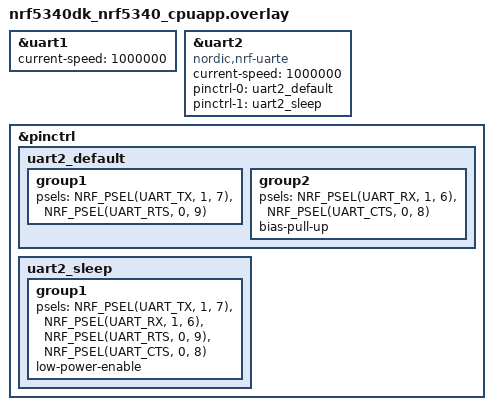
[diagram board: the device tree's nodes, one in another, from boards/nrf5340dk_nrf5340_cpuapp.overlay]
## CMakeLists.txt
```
#
# Copyright (c) 2025 Nordic Semiconductor ASA
#
# SPDX-License-Identifier: LicenseRef-Nordic-5-Clause
#

cmake_minimum_required(VERSION 3.20.0)

find_package(Zephyr REQUIRED HINTS $ENV{ZEPHYR_BASE})
project(zbus_uart_forwarder_dev_a)


zephyr_library_include_directories(
    src
    ../common
)

# Define which device this is
zephyr_compile_definitions(ZBUS_DEVICE_A=1)

target_sources(app PRIVATE src/main.c)
```

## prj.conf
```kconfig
# Copyright (c) 2025 Nordic Semiconductor ASA
# SPDX-License-Identifier: LicenseRef-Nordic-5-Clause


CONFIG_LOG=y
# CONFIG_LOG_MODE_MINIMAL=y
CONFIG_LOG_DBG_COLOR_BLUE=y

CONFIG_SERIAL=y
CONFIG_UART_ASYNC_API=y

CONFIG_UART_1_NRF_ASYNC_LOW_POWER=y
CONFIG_UART_2_NRF_ASYNC_LOW_POWER=y

CONFIG_ZBUS=y

CONFIG_ZBUS_MULTIDOMAIN=y
CONFIG_ZBUS_MULTIDOMAIN_UART=y
CONFIG_ZBUS_MULTIDOMAIN_LOG_LEVEL_DBG=n
```

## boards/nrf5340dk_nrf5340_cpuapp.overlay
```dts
&uart1 {
    status = "okay";
	current-speed = <1000000>;
    /delete-property/ hw-flow-control;
};

&uart2 {
	compatible = "nordic,nrf-uarte";
    status = "okay";
	current-speed = <1000000>;
	pinctrl-0 = <&uart2_default>;
	pinctrl-1 = <&uart2_sleep>;
	pinctrl-names = "default", "sleep";
    /delete-property/ hw-flow-control;
};

&pinctrl {
	uart2_default: uart2_default {
		group1 {
			psels = <NRF_PSEL(UART_TX, 1, 7)>,
				<NRF_PSEL(UART_RTS, 0, 9)>;
		};

		group2 {
			psels = <NRF_PSEL(UART_RX, 1, 6)>,
				<NRF_PSEL(UART_CTS, 0, 8)>;
			bias-pull-up;
		};
	};

	uart2_sleep: uart2_sleep {
		group1 {
			psels = <NRF_PSEL(UART_TX, 1, 7)>,
				<NRF_PSEL(UART_RX, 1, 6)>,
				<NRF_PSEL(UART_RTS, 0, 9)>,
				<NRF_PSEL(UART_CTS, 0, 8)>;
			low-power-enable;
		};
	};
};
```

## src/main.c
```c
#include <zephyr/kernel.h>
#include <zephyr/logging/log.h>
#include <string.h>
#include <zephyr/zbus/zbus.h>
#include <zephyr/zbus/multidomain/zbus_multidomain.h>

#include "common.h"

LOG_MODULE_REGISTER(main, LOG_LEVEL_DBG);

/* NOTE: Shared channels request_channel and response_channel are defined in common.h */

/* Set up proxy agent for UART1 and add response channel to be forwarded */
ZBUS_PROXY_AGENT_DEFINE(uart1_proxy, ZBUS_MULTIDOMAIN_TYPE_UART, uart1);
ZBUS_PROXY_ADD_CHANNEL(uart1_proxy, request_channel);

/* Log response data coming from the response channel */
void uart_forwarder_listener_cb(const struct zbus_channel *chan)
{
	LOG_INF("Received message on channel %s", chan->name);
	const struct response_data *data = zbus_chan_const_msg(chan);
	LOG_INF("Response ID: %d, Value: %d", data->response_id, data->value);
}
ZBUS_LISTENER_DEFINE(uart_forwarder_listener, uart_forwarder_listener_cb);
ZBUS_CHAN_ADD_OBS(response_channel, uart_forwarder_listener, 0);

bool print_channel_info(const struct zbus_channel *chan)
{
	if (chan == NULL) {
		LOG_ERR("Channel is NULL");
		return false;
	}
	LOG_INF("Channel %s is a %s channel", chan->name,
		ZBUS_CHANNEL_IS_SHADOW(chan) ? "shadow" : "master");
	return true;
}

int main(void)
{
	LOG_INF("ZBUS Multidomain UART Forwarder Sample Application");
	zbus_iterate_over_channels(print_channel_info);

	struct request_data data = {.request_id = 1, .min_value = -1, .max_value = 1};

	while (1) {

		int ret = zbus_chan_pub(&request_channel, &data, K_MSEC(100));
		if (ret < 0) {
			LOG_ERR("Failed to publish on channel %s: %d", request_channel.name, ret);
		} else {
			LOG_INF("Published on channel %s. Request ID=%d, Min=%d, Max=%d",
				request_channel.name, data.request_id, data.min_value,
				data.max_value);
		}

		data.request_id++;
		data.min_value -= 1;
		data.max_value += 1;
		k_sleep(K_SECONDS(5));
	}
	return 0;
}
```
